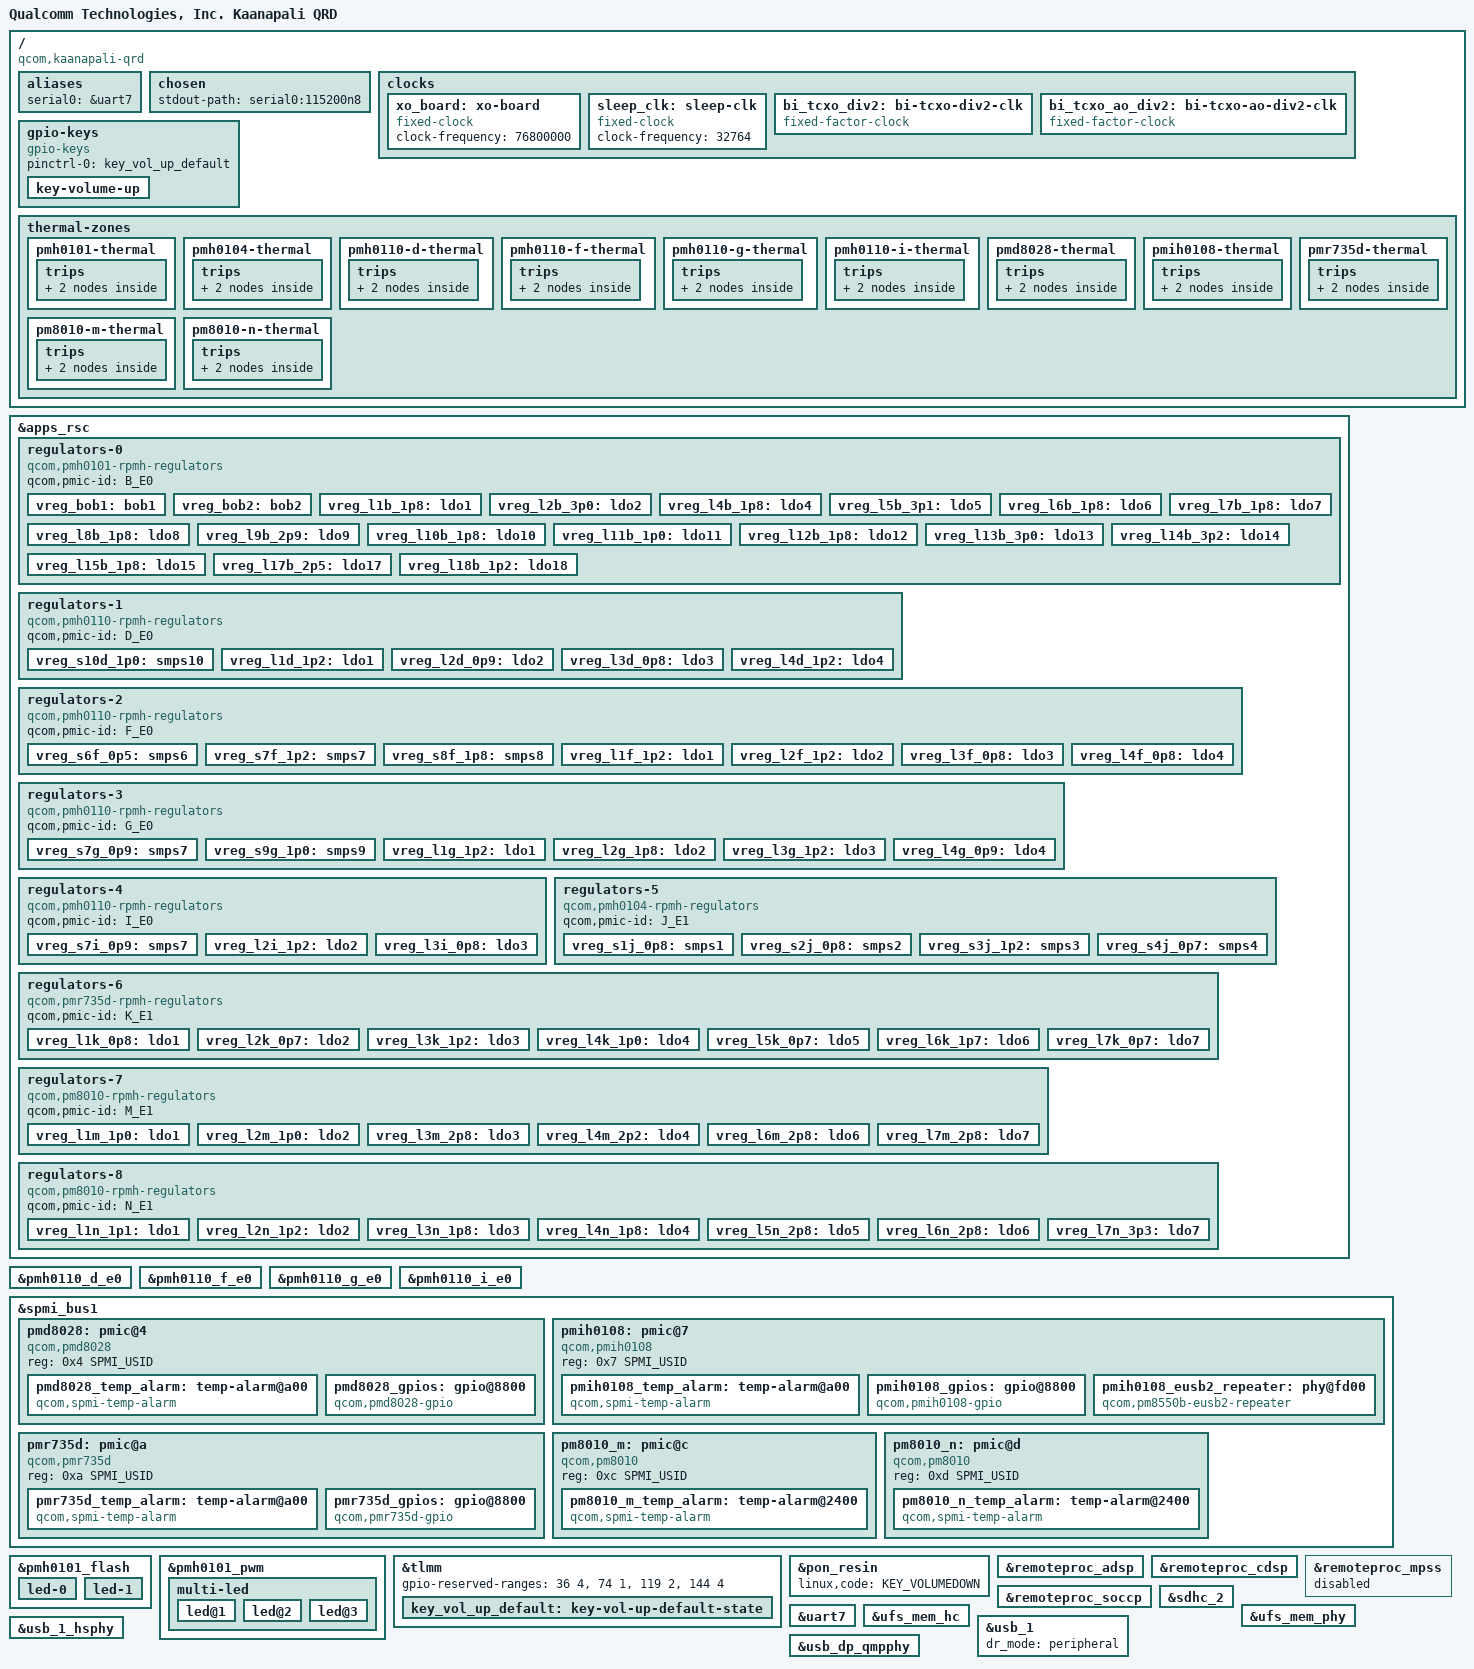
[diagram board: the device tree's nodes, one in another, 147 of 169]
// SPDX-License-Identifier: BSD-3-Clause
/*
 * Copyright (c) Qualcomm Technologies, Inc. and/or its subsidiaries.
 */

/dts-v1/;

#include <dt-bindings/gpio/gpio.h>
#include <dt-bindings/input/linux-event-codes.h>
#include <dt-bindings/leds/common.h>
#include <dt-bindings/regulator/qcom,rpmh-regulator.h>
#include "kaanapali.dtsi"

#define PMH0110_D_E0_SID 3
#define PMH0110_F_E0_SID 5
#define PMH0110_G_E0_SID 6
#define PMH0110_I_E0_SID 8
#define PMH0104_J_E1_SID 9

#include "pmk8850.dtsi"
#include "pmh0101.dtsi"
#include "pmh0110.dtsi"
#include "pmh0104.dtsi"

/ {
	model = "Qualcomm Technologies, Inc. Kaanapali QRD";
	compatible = "qcom,kaanapali-qrd", "qcom,kaanapali";
	chassis-type = "handset";

	aliases {
		serial0 = &uart7;
	};

	chosen {
		stdout-path = "serial0:115200n8";
	};

	clocks {
		xo_board: xo-board {
			compatible = "fixed-clock";
			clock-frequency = <76800000>;
			#clock-cells = <0>;
		};

		sleep_clk: sleep-clk {
			compatible = "fixed-clock";
			clock-frequency = <32764>;
			#clock-cells = <0>;
		};

		bi_tcxo_div2: bi-tcxo-div2-clk {
			compatible = "fixed-factor-clock";
			#clock-cells = <0>;

			clocks = <&rpmhcc RPMH_CXO_CLK>;
			clock-mult = <1>;
			clock-div = <2>;
		};

		bi_tcxo_ao_div2: bi-tcxo-ao-div2-clk {
			compatible = "fixed-factor-clock";
			#clock-cells = <0>;

			clocks = <&rpmhcc RPMH_CXO_CLK_A>;
			clock-mult = <1>;
			clock-div = <2>;
		};
	};

	gpio-keys {
		compatible = "gpio-keys";

		pinctrl-0 = <&key_vol_up_default>;
		pinctrl-names = "default";

		key-volume-up {
			label = "Volume Up";
			linux,code = <KEY_VOLUMEUP>;
			gpios = <&tlmm 101 GPIO_ACTIVE_LOW>;
			debounce-interval = <15>;
			linux,can-disable;
			wakeup-source;
		};
	};

	thermal-zones {
		pmh0101-thermal {
			polling-delay-passive = <100>;

			thermal-sensors = <&pmh0101_temp_alarm>;

			trips {
				trip0 {
					temperature = <95000>;
					hysteresis = <0>;
					type = "passive";
				};

				trip1 {
					temperature = <115000>;
					hysteresis = <0>;
					type = "hot";
				};
			};
		};

		pmh0104-thermal {
			polling-delay-passive = <100>;

			thermal-sensors = <&pmh0104_j_e1_temp_alarm>;

			trips {
				trip0 {
					temperature = <95000>;
					hysteresis = <0>;
					type = "passive";
				};

				trip1 {
					temperature = <115000>;
					hysteresis = <0>;
					type = "hot";
				};
			};
		};

		pmh0110-d-thermal {
			polling-delay-passive = <100>;

			thermal-sensors = <&pmh0110_d_e0_temp_alarm>;

			trips {
				trip0 {
					temperature = <95000>;
					hysteresis = <0>;
					type = "passive";
				};

				trip1 {
					temperature = <115000>;
					hysteresis = <0>;
					type = "hot";
				};
			};
		};

		pmh0110-f-thermal {
			polling-delay-passive = <100>;

			thermal-sensors = <&pmh0110_f_e0_temp_alarm>;

			trips {
				trip0 {
					temperature = <95000>;
					hysteresis = <0>;
					type = "passive";
				};

				trip1 {
					temperature = <115000>;
					hysteresis = <0>;
					type = "hot";
				};
			};
		};

		pmh0110-g-thermal {
			polling-delay-passive = <100>;

			thermal-sensors = <&pmh0110_g_e0_temp_alarm>;

			trips {
				trip0 {
					temperature = <95000>;
					hysteresis = <0>;
					type = "passive";
				};

				trip1 {
					temperature = <115000>;
					hysteresis = <0>;
					type = "hot";
				};
			};
		};

		pmh0110-i-thermal {
			polling-delay-passive = <100>;

			thermal-sensors = <&pmh0110_i_e0_temp_alarm>;

			trips {
				trip0 {
					temperature = <95000>;
					hysteresis = <0>;
					type = "passive";
				};

				trip1 {
					temperature = <115000>;
					hysteresis = <0>;
					type = "hot";
				};
			};
		};

		pmd8028-thermal {
			polling-delay-passive = <100>;
			thermal-sensors = <&pmd8028_temp_alarm>;

			trips {
				pmd8028_trip0: trip0 {
					temperature = <95000>;
					hysteresis = <0>;
					type = "passive";
				};

				pmd8028_trip1: trip1 {
					temperature = <115000>;
					hysteresis = <0>;
					type = "hot";
				};
			};
		};

		pmih0108-thermal {
			polling-delay-passive = <100>;
			thermal-sensors = <&pmih0108_temp_alarm>;

			trips {
				trip0 {
					temperature = <95000>;
					hysteresis = <0>;
					type = "passive";
				};

				trip1 {
					temperature = <115000>;
					hysteresis = <0>;
					type = "hot";
				};
			};
		};

		pmr735d-thermal {
			polling-delay-passive = <100>;

			thermal-sensors = <&pmr735d_temp_alarm>;

			trips {
				trip0 {
					temperature = <95000>;
					hysteresis = <0>;
					type = "passive";
				};

				trip1 {
					temperature = <115000>;
					hysteresis = <0>;
					type = "hot";
				};
			};
		};

		pm8010-m-thermal {
			polling-delay-passive = <100>;

			thermal-sensors = <&pm8010_m_temp_alarm>;

			trips {
				trip0 {
					temperature = <95000>;
					hysteresis = <0>;
					type = "passive";
				};

				trip1 {
					temperature = <115000>;
					hysteresis = <0>;
					type = "hot";
				};
			};
		};

		pm8010-n-thermal {
			polling-delay-passive = <100>;

			thermal-sensors = <&pm8010_n_temp_alarm>;

			trips {
				trip0 {
					temperature = <95000>;
					hysteresis = <0>;
					type = "passive";
				};

				trip1 {
					temperature = <115000>;
					hysteresis = <0>;
					type = "hot";
				};
			};
		};
	};
};

&apps_rsc {
	regulators-0 {
		compatible = "qcom,pmh0101-rpmh-regulators";

		qcom,pmic-id = "B_E0";

		vreg_bob1: bob1 {
			regulator-name = "vreg_bob1";
			regulator-min-microvolt = <3008000>;
			regulator-max-microvolt = <4000000>;
			regulator-initial-mode = <RPMH_REGULATOR_MODE_HPM>;
		};

		vreg_bob2: bob2 {
			regulator-name = "vreg_bob2";
			regulator-min-microvolt = <2704000>;
			regulator-max-microvolt = <3552000>;
			regulator-initial-mode = <RPMH_REGULATOR_MODE_HPM>;
		};

		vreg_l1b_1p8: ldo1 {
			regulator-name = "vreg_l1b_1p8";
			regulator-min-microvolt = <1800000>;
			regulator-max-microvolt = <1800000>;
			regulator-initial-mode = <RPMH_REGULATOR_MODE_AUTO>;
			regulator-allow-set-load;
			regulator-allowed-modes = <RPMH_REGULATOR_MODE_LPM
						   RPMH_REGULATOR_MODE_AUTO>;
		};

		vreg_l2b_3p0: ldo2 {
			regulator-name = "vreg_l2b_3p0";
			regulator-min-microvolt = <3008000>;
			regulator-max-microvolt = <3048000>;
			regulator-initial-mode = <RPMH_REGULATOR_MODE_AUTO>;
			regulator-allow-set-load;
			regulator-allowed-modes = <RPMH_REGULATOR_MODE_LPM
						   RPMH_REGULATOR_MODE_AUTO>;
		};

		vreg_l4b_1p8: ldo4 {
			regulator-name = "vreg_l4b_1p8";
			regulator-min-microvolt = <1800000>;
			regulator-max-microvolt = <1800000>;
			regulator-initial-mode = <RPMH_REGULATOR_MODE_AUTO>;
			regulator-allow-set-load;
			regulator-allowed-modes = <RPMH_REGULATOR_MODE_LPM
						   RPMH_REGULATOR_MODE_AUTO>;
		};

		vreg_l5b_3p1: ldo5 {
			regulator-name = "vreg_l5b_3p1";
			regulator-min-microvolt = <3100000>;
			regulator-max-microvolt = <3148000>;
			regulator-initial-mode = <RPMH_REGULATOR_MODE_AUTO>;
			regulator-allow-set-load;
			regulator-allowed-modes = <RPMH_REGULATOR_MODE_LPM
						   RPMH_REGULATOR_MODE_AUTO>;
		};

		vreg_l6b_1p8: ldo6 {
			regulator-name = "vreg_l6b_1p8";
			regulator-min-microvolt = <1800000>;
			regulator-max-microvolt = <3008000>;
			regulator-initial-mode = <RPMH_REGULATOR_MODE_AUTO>;
			regulator-allow-set-load;
			regulator-allowed-modes = <RPMH_REGULATOR_MODE_LPM
						   RPMH_REGULATOR_MODE_AUTO>;
		};

		vreg_l7b_1p8: ldo7 {
			regulator-name = "vreg_l7b_1p8";
			regulator-min-microvolt = <1800000>;
			regulator-max-microvolt = <3008000>;
			regulator-initial-mode = <RPMH_REGULATOR_MODE_AUTO>;
			regulator-allow-set-load;
			regulator-allowed-modes = <RPMH_REGULATOR_MODE_LPM
						   RPMH_REGULATOR_MODE_AUTO>;
		};

		vreg_l8b_1p8: ldo8 {
			regulator-name = "vreg_l8b_1p8";
			regulator-min-microvolt = <1800000>;
			regulator-max-microvolt = <3008000>;
			regulator-initial-mode = <RPMH_REGULATOR_MODE_AUTO>;
			regulator-allow-set-load;
			regulator-allowed-modes = <RPMH_REGULATOR_MODE_LPM
						   RPMH_REGULATOR_MODE_AUTO>;
		};

		vreg_l9b_2p9: ldo9 {
			regulator-name = "vreg_l9b_2p9";
			regulator-min-microvolt = <2960000>;
			regulator-max-microvolt = <3008000>;
			regulator-initial-mode = <RPMH_REGULATOR_MODE_HPM>;
			regulator-allow-set-load;
			regulator-allowed-modes = <RPMH_REGULATOR_MODE_LPM
						   RPMH_REGULATOR_MODE_HPM>;
		};

		vreg_l10b_1p8: ldo10 {
			regulator-name = "vreg_l10b_1p8";
			regulator-min-microvolt = <1800000>;
			regulator-max-microvolt = <1800000>;
			regulator-initial-mode = <RPMH_REGULATOR_MODE_AUTO>;
			regulator-allow-set-load;
			regulator-allowed-modes = <RPMH_REGULATOR_MODE_LPM
						   RPMH_REGULATOR_MODE_AUTO>;
		};

		vreg_l11b_1p0: ldo11 {
			regulator-name = "vreg_l11b_1p0";
			regulator-min-microvolt = <1000000>;
			regulator-max-microvolt = <1292000>;
			regulator-initial-mode = <RPMH_REGULATOR_MODE_AUTO>;
			regulator-allow-set-load;
			regulator-allowed-modes = <RPMH_REGULATOR_MODE_LPM
						   RPMH_REGULATOR_MODE_AUTO>;
		};

		vreg_l12b_1p8: ldo12 {
			regulator-name = "vreg_l12b_1p8";
			regulator-min-microvolt = <1200000>;
			regulator-max-microvolt = <1800000>;
			regulator-initial-mode = <RPMH_REGULATOR_MODE_AUTO>;
			regulator-allow-set-load;
			regulator-allowed-modes = <RPMH_REGULATOR_MODE_LPM
						   RPMH_REGULATOR_MODE_AUTO>;
		};

		vreg_l13b_3p0: ldo13 {
			regulator-name = "vreg_l13b_3p0";
			regulator-min-microvolt = <3000000>;
			regulator-max-microvolt = <3000000>;
			regulator-initial-mode = <RPMH_REGULATOR_MODE_AUTO>;
			regulator-allow-set-load;
			regulator-allowed-modes = <RPMH_REGULATOR_MODE_LPM
						   RPMH_REGULATOR_MODE_AUTO>;
		};

		vreg_l14b_3p2: ldo14 {
			regulator-name = "vreg_l14b_3p2";
			regulator-min-microvolt = <3200000>;
			regulator-max-microvolt = <3200000>;
			regulator-initial-mode = <RPMH_REGULATOR_MODE_AUTO>;
			regulator-allow-set-load;
			regulator-allowed-modes = <RPMH_REGULATOR_MODE_LPM
						   RPMH_REGULATOR_MODE_AUTO>;
		};

		vreg_l15b_1p8: ldo15 {
			regulator-name = "vreg_l15b_1p8";
			regulator-min-microvolt = <1800000>;
			regulator-max-microvolt = <1800000>;
			regulator-initial-mode = <RPMH_REGULATOR_MODE_AUTO>;
			regulator-allow-set-load;
			regulator-allowed-modes = <RPMH_REGULATOR_MODE_LPM
						   RPMH_REGULATOR_MODE_AUTO>;
		};

		vreg_l17b_2p5: ldo17 {
			regulator-name = "vreg_l17b_2p5";
			regulator-min-microvolt = <2504000>;
			regulator-max-microvolt = <2504000>;
			regulator-initial-mode = <RPMH_REGULATOR_MODE_HPM>;
			regulator-allow-set-load;
			regulator-allowed-modes = <RPMH_REGULATOR_MODE_LPM
						   RPMH_REGULATOR_MODE_HPM>;
		};

		vreg_l18b_1p2: ldo18 {
			regulator-name = "vreg_l18b_1p2";
			regulator-min-microvolt = <1200000>;
			regulator-max-microvolt = <1200000>;
			regulator-initial-mode = <RPMH_REGULATOR_MODE_AUTO>;
			regulator-allow-set-load;
			regulator-allowed-modes = <RPMH_REGULATOR_MODE_LPM
						   RPMH_REGULATOR_MODE_AUTO>;
		};
	};

	regulators-1 {
		compatible = "qcom,pmh0110-rpmh-regulators";

		qcom,pmic-id = "D_E0";

		vreg_s10d_1p0: smps10 {
			regulator-name = "vreg_s10d_1p0";
			regulator-min-microvolt = <1000000>;
			regulator-max-microvolt = <1100000>;
			regulator-initial-mode = <RPMH_REGULATOR_MODE_HPM>;
		};

		vreg_l1d_1p2: ldo1 {
			regulator-name = "vreg_l1d_1p2";
			regulator-min-microvolt = <1200000>;
			regulator-max-microvolt = <1256000>;
			regulator-initial-mode = <RPMH_REGULATOR_MODE_AUTO>;
			regulator-allow-set-load;
			regulator-allowed-modes = <RPMH_REGULATOR_MODE_LPM
						   RPMH_REGULATOR_MODE_AUTO>;
		};

		vreg_l2d_0p9: ldo2 {
			regulator-name = "vreg_l2d_0p9";
			regulator-min-microvolt = <912000>;
			regulator-max-microvolt = <958000>;
			regulator-initial-mode = <RPMH_REGULATOR_MODE_AUTO>;
			regulator-allow-set-load;
			regulator-allowed-modes = <RPMH_REGULATOR_MODE_LPM
						   RPMH_REGULATOR_MODE_AUTO>;
		};

		vreg_l3d_0p8: ldo3 {
			regulator-name = "vreg_l3d_0p8";
			regulator-min-microvolt = <880000>;
			regulator-max-microvolt = <880000>;
			regulator-initial-mode = <RPMH_REGULATOR_MODE_AUTO>;
			regulator-allow-set-load;
			regulator-allowed-modes = <RPMH_REGULATOR_MODE_LPM
						   RPMH_REGULATOR_MODE_AUTO>;
		};

		vreg_l4d_1p2: ldo4 {
			regulator-name = "vreg_l4d_1p2";
			regulator-min-microvolt = <1200000>;
			regulator-max-microvolt = <1200000>;
			regulator-initial-mode = <RPMH_REGULATOR_MODE_AUTO>;
			regulator-allow-set-load;
			regulator-allowed-modes = <RPMH_REGULATOR_MODE_LPM
						   RPMH_REGULATOR_MODE_AUTO>;
		};
	};

	regulators-2 {
		compatible = "qcom,pmh0110-rpmh-regulators";

		qcom,pmic-id = "F_E0";

		vreg_s6f_0p5: smps6 {
			regulator-name = "vreg_s6f_0p5";
			regulator-min-microvolt = <300000>;
			regulator-max-microvolt = <570000>;
			regulator-initial-mode = <RPMH_REGULATOR_MODE_HPM>;
		};

		vreg_s7f_1p2: smps7 {
			regulator-name = "vreg_s7f_1p2";
			regulator-min-microvolt = <1224000>;
			regulator-max-microvolt = <1372000>;
			regulator-initial-mode = <RPMH_REGULATOR_MODE_HPM>;
		};

		vreg_s8f_1p8: smps8 {
			regulator-name = "vreg_s8f_1p8";
			regulator-min-microvolt = <1800000>;
			regulator-max-microvolt = <2000000>;
			regulator-initial-mode = <RPMH_REGULATOR_MODE_HPM>;
		};

		vreg_l1f_1p2: ldo1 {
			regulator-name = "vreg_l1f_1p2";
			regulator-min-microvolt = <1200000>;
			regulator-max-microvolt = <1200000>;
			regulator-initial-mode = <RPMH_REGULATOR_MODE_AUTO>;
			regulator-allow-set-load;
			regulator-allowed-modes = <RPMH_REGULATOR_MODE_LPM
						   RPMH_REGULATOR_MODE_AUTO>;
		};

		vreg_l2f_1p2: ldo2 {
			regulator-name = "vreg_l2f_1p2";
			regulator-min-microvolt = <1200000>;
			regulator-max-microvolt = <1200000>;
			regulator-initial-mode = <RPMH_REGULATOR_MODE_AUTO>;
			regulator-allow-set-load;
			regulator-allowed-modes = <RPMH_REGULATOR_MODE_LPM
						   RPMH_REGULATOR_MODE_AUTO>;
		};

		vreg_l3f_0p8: ldo3 {
			regulator-name = "vreg_l3f_0p8";
			regulator-min-microvolt = <880000>;
			regulator-max-microvolt = <936000>;
			regulator-initial-mode = <RPMH_REGULATOR_MODE_AUTO>;
			regulator-allow-set-load;
			regulator-allowed-modes = <RPMH_REGULATOR_MODE_LPM
						   RPMH_REGULATOR_MODE_AUTO>;
		};

		vreg_l4f_0p8: ldo4 {
			regulator-name = "vreg_l4f_0p8";
			regulator-min-microvolt = <880000>;
			regulator-max-microvolt = <912000>;
			regulator-initial-mode = <RPMH_REGULATOR_MODE_AUTO>;
			regulator-allow-set-load;
			regulator-allowed-modes = <RPMH_REGULATOR_MODE_LPM
						   RPMH_REGULATOR_MODE_AUTO>;
		};
	};

	regulators-3 {
		compatible = "qcom,pmh0110-rpmh-regulators";

		qcom,pmic-id = "G_E0";

		vreg_s7g_0p9: smps7 {
			regulator-name = "vreg_s7g_0p9";
			regulator-min-microvolt = <880000>;
			regulator-max-microvolt = <1100000>;
			regulator-initial-mode = <RPMH_REGULATOR_MODE_HPM>;
		};

		vreg_s9g_1p0: smps9 {
			regulator-name = "vreg_s9g_1p0";
			regulator-min-microvolt = <1000000>;
			regulator-max-microvolt = <1100000>;
			regulator-initial-mode = <RPMH_REGULATOR_MODE_HPM>;
		};

		vreg_l1g_1p2: ldo1 {
			regulator-name = "vreg_l1g_1p2";
			regulator-min-microvolt = <1200000>;
			regulator-max-microvolt = <1200000>;
			regulator-initial-mode = <RPMH_REGULATOR_MODE_AUTO>;
			regulator-allow-set-load;
			regulator-allowed-modes = <RPMH_REGULATOR_MODE_LPM
						   RPMH_REGULATOR_MODE_AUTO>;
		};

		vreg_l2g_1p8: ldo2 {
			regulator-name = "vreg_l2g_1p8";
			regulator-min-microvolt = <1800000>;
			regulator-max-microvolt = <1800000>;
			regulator-initial-mode = <RPMH_REGULATOR_MODE_AUTO>;
			regulator-allow-set-load;
			regulator-allowed-modes = <RPMH_REGULATOR_MODE_LPM
						   RPMH_REGULATOR_MODE_AUTO>;
		};

		vreg_l3g_1p2: ldo3 {
			regulator-name = "vreg_l3g_1p2";
			regulator-min-microvolt = <1200000>;
			regulator-max-microvolt = <1200000>;
			regulator-initial-mode = <RPMH_REGULATOR_MODE_AUTO>;
			regulator-allow-set-load;
			regulator-allowed-modes = <RPMH_REGULATOR_MODE_LPM
						   RPMH_REGULATOR_MODE_AUTO>;
		};

		vreg_l4g_0p9: ldo4 {
			regulator-name = "vreg_l4g_0p9";
			regulator-min-microvolt = <880000>;
			regulator-max-microvolt = <920000>;
			regulator-initial-mode = <RPMH_REGULATOR_MODE_AUTO>;
			regulator-allow-set-load;
			regulator-allowed-modes = <RPMH_REGULATOR_MODE_LPM
						   RPMH_REGULATOR_MODE_AUTO>;
		};
	};

	regulators-4 {
		compatible = "qcom,pmh0110-rpmh-regulators";

		qcom,pmic-id = "I_E0";

		vreg_s7i_0p9: smps7 {
			regulator-name = "vreg_s7i_0p9";
			regulator-min-microvolt = <900000>;
			regulator-max-microvolt = <972000>;
			regulator-initial-mode = <RPMH_REGULATOR_MODE_HPM>;
		};

		vreg_l2i_1p2: ldo2 {
			regulator-name = "vreg_l2i_1p2";
			regulator-min-microvolt = <1200000>;
			regulator-max-microvolt = <1200000>;
			regulator-initial-mode = <RPMH_REGULATOR_MODE_AUTO>;
			regulator-allow-set-load;
			regulator-allowed-modes = <RPMH_REGULATOR_MODE_LPM
						   RPMH_REGULATOR_MODE_AUTO>;
		};

		vreg_l3i_0p8: ldo3 {
			regulator-name = "vreg_l3i_0p8";
			regulator-min-microvolt = <880000>;
			regulator-max-microvolt = <920000>;
			regulator-initial-mode = <RPMH_REGULATOR_MODE_AUTO>;
			regulator-allow-set-load;
			regulator-allowed-modes = <RPMH_REGULATOR_MODE_LPM
						   RPMH_REGULATOR_MODE_AUTO>;
		};
	};

	regulators-5 {
		compatible = "qcom,pmh0104-rpmh-regulators";

		qcom,pmic-id = "J_E1";

		vreg_s1j_0p8: smps1 {
			regulator-name = "vreg_s1j_0p8";
			regulator-min-microvolt = <400000>;
			regulator-max-microvolt = <1000000>;
			regulator-initial-mode = <RPMH_REGULATOR_MODE_HPM>;
		};

		vreg_s2j_0p8: smps2 {
			regulator-name = "vreg_s2j_0p8";
			regulator-min-microvolt = <500000>;
			regulator-max-microvolt = <1100000>;
			regulator-initial-mode = <RPMH_REGULATOR_MODE_HPM>;
		};

		vreg_s3j_1p2: smps3 {
			regulator-name = "vreg_s3j_1p2";
			regulator-min-microvolt = <1200000>;
			regulator-max-microvolt = <1300000>;
			regulator-initial-mode = <RPMH_REGULATOR_MODE_HPM>;
		};

		vreg_s4j_0p7: smps4 {
			regulator-name = "vreg_s4j_0p7";
			regulator-min-microvolt = <300000>;
			regulator-max-microvolt = <1000000>;
			regulator-initial-mode = <RPMH_REGULATOR_MODE_HPM>;
		};
	};

	regulators-6 {
		compatible = "qcom,pmr735d-rpmh-regulators";

		qcom,pmic-id = "K_E1";

		vreg_l1k_0p8: ldo1 {
			regulator-name = "vreg_l1k_0p8";
			regulator-min-microvolt = <300000>;
			regulator-max-microvolt = <1100000>;
			regulator-initial-mode = <RPMH_REGULATOR_MODE_HPM>;
			regulator-allow-set-load;
			regulator-allowed-modes = <RPMH_REGULATOR_MODE_LPM
						   RPMH_REGULATOR_MODE_HPM>;
		};

		vreg_l2k_0p7: ldo2 {
			regulator-name = "vreg_l2k_0p7";
			regulator-min-microvolt = <700000>;
			regulator-max-microvolt = <1000000>;
			regulator-initial-mode = <RPMH_REGULATOR_MODE_HPM>;
			regulator-allow-set-load;
			regulator-allowed-modes = <RPMH_REGULATOR_MODE_LPM
						   RPMH_REGULATOR_MODE_HPM>;
		};

		vreg_l3k_1p2: ldo3 {
			regulator-name = "vreg_l3k_1p2";
			regulator-min-microvolt = <1200000>;
			regulator-max-microvolt = <1200000>;
			regulator-initial-mode = <RPMH_REGULATOR_MODE_HPM>;
			regulator-allow-set-load;
			regulator-allowed-modes = <RPMH_REGULATOR_MODE_LPM
						   RPMH_REGULATOR_MODE_HPM>;
		};

		vreg_l4k_1p0: ldo4 {
			regulator-name = "vreg_l4k_1p0";
			regulator-min-microvolt = <1000000>;
			regulator-max-microvolt = <1200000>;
			regulator-initial-mode = <RPMH_REGULATOR_MODE_HPM>;
			regulator-allow-set-load;
			regulator-allowed-modes = <RPMH_REGULATOR_MODE_LPM
						   RPMH_REGULATOR_MODE_HPM>;
		};

		vreg_l5k_0p7: ldo5 {
			regulator-name = "vreg_l5k_0p7";
			regulator-min-microvolt = <700000>;
			regulator-max-microvolt = <1000000>;
			regulator-initial-mode = <RPMH_REGULATOR_MODE_HPM>;
			regulator-allow-set-load;
			regulator-allowed-modes = <RPMH_REGULATOR_MODE_LPM
						   RPMH_REGULATOR_MODE_HPM>;
		};

		vreg_l6k_1p7: ldo6 {
			regulator-name = "vreg_l6k_1p7";
			regulator-min-microvolt = <1700000>;
			regulator-max-microvolt = <2000000>;
			regulator-initial-mode = <RPMH_REGULATOR_MODE_HPM>;
			regulator-allow-set-load;
			regulator-allowed-modes = <RPMH_REGULATOR_MODE_LPM
						   RPMH_REGULATOR_MODE_HPM>;
		};

		vreg_l7k_0p7: ldo7 {
			regulator-name = "vreg_l7k_0p7";
			regulator-min-microvolt = <700000>;
			regulator-max-microvolt = <848000>;
			regulator-initial-mode = <RPMH_REGULATOR_MODE_HPM>;
			regulator-allow-set-load;
			regulator-allowed-modes = <RPMH_REGULATOR_MODE_LPM
						   RPMH_REGULATOR_MODE_HPM>;
		};
	};

	regulators-7 {
		compatible = "qcom,pm8010-rpmh-regulators";

		qcom,pmic-id = "M_E1";

		vreg_l1m_1p0: ldo1 {
			regulator-name = "vreg_l1m_1p0";
			regulator-min-microvolt = <1000000>;
			regulator-max-microvolt = <1100000>;
			regulator-initial-mode = <RPMH_REGULATOR_MODE_HPM>;
			regulator-allow-set-load;
			regulator-allowed-modes = <RPMH_REGULATOR_MODE_LPM
						   RPMH_REGULATOR_MODE_HPM>;
		};

		vreg_l2m_1p0: ldo2 {
			regulator-name = "vreg_l2m_1p0";
			regulator-min-microvolt = <1096000>;
			regulator-max-microvolt = <1104000>;
			regulator-initial-mode = <RPMH_REGULATOR_MODE_HPM>;
			regulator-allow-set-load;
			regulator-allowed-modes = <RPMH_REGULATOR_MODE_LPM
						   RPMH_REGULATOR_MODE_HPM>;
		};

		vreg_l3m_2p8: ldo3 {
			regulator-name = "vreg_l3m_2p8";
			regulator-min-microvolt = <2800000>;
			regulator-max-microvolt = <2900000>;
			regulator-initial-mode = <RPMH_REGULATOR_MODE_HPM>;
		};

		vreg_l4m_2p2: ldo4 {
			regulator-name = "vreg_l4m_2p2";
			regulator-min-microvolt = <2200000>;
			regulator-max-microvolt = <2200000>;
			regulator-initial-mode = <RPMH_REGULATOR_MODE_HPM>;
		};

		vreg_l6m_2p8: ldo6 {
			regulator-name = "vreg_l6m_2p8";
			regulator-min-microvolt = <2800000>;
			regulator-max-microvolt = <2800000>;
			regulator-initial-mode = <RPMH_REGULATOR_MODE_HPM>;
		};

		vreg_l7m_2p8: ldo7 {
			regulator-name = "vreg_l7m_2p8";
			regulator-min-microvolt = <2800000>;
			regulator-max-microvolt = <2800000>;
			regulator-initial-mode = <RPMH_REGULATOR_MODE_HPM>;
		};
	};

	regulators-8 {
		compatible = "qcom,pm8010-rpmh-regulators";

		qcom,pmic-id = "N_E1";

		vreg_l1n_1p1: ldo1 {
			regulator-name = "vreg_l1n_1p1";
			regulator-min-microvolt = <1096000>;
			regulator-max-microvolt = <1104000>;
			regulator-initial-mode = <RPMH_REGULATOR_MODE_HPM>;
			regulator-allow-set-load;
			regulator-allowed-modes = <RPMH_REGULATOR_MODE_LPM
						   RPMH_REGULATOR_MODE_HPM>;
		};

		vreg_l2n_1p2: ldo2 {
			regulator-name = "vreg_l2n_1p2";
			regulator-min-microvolt = <1200000>;
			regulator-max-microvolt = <1200000>;
			regulator-initial-mode = <RPMH_REGULATOR_MODE_HPM>;
			regulator-allow-set-load;
			regulator-allowed-modes = <RPMH_REGULATOR_MODE_LPM
						   RPMH_REGULATOR_MODE_HPM>;
		};

		vreg_l3n_1p8: ldo3 {
			regulator-name = "vreg_l3n_1p8";
			regulator-min-microvolt = <1800000>;
			regulator-max-microvolt = <1800000>;
			regulator-initial-mode = <RPMH_REGULATOR_MODE_HPM>;
		};

		vreg_l4n_1p8: ldo4 {
			regulator-name = "vreg_l4n_1p8";
			regulator-min-microvolt = <1800000>;
			regulator-max-microvolt = <1800000>;
			regulator-initial-mode = <RPMH_REGULATOR_MODE_HPM>;
		};

		vreg_l5n_2p8: ldo5 {
			regulator-name = "vreg_l5n_2p8";
			regulator-min-microvolt = <2800000>;
			regulator-max-microvolt = <2800000>;
			regulator-initial-mode = <RPMH_REGULATOR_MODE_HPM>;
		};

		vreg_l6n_2p8: ldo6 {
			regulator-name = "vreg_l6n_2p8";
			regulator-min-microvolt = <2800000>;
			regulator-max-microvolt = <2800000>;
			regulator-initial-mode = <RPMH_REGULATOR_MODE_HPM>;
		};

		vreg_l7n_3p3: ldo7 {
			regulator-name = "vreg_l7n_3p3";
			regulator-min-microvolt = <3304000>;
			regulator-max-microvolt = <3304000>;
			regulator-initial-mode = <RPMH_REGULATOR_MODE_HPM>;
		};
	};
};

&pmh0110_d_e0 {
	status = "okay";
};

&pmh0110_f_e0 {
	status = "okay";
};

&pmh0110_g_e0 {
	status = "okay";
};

&pmh0110_i_e0 {
	status = "okay";
};

&spmi_bus1 {
	pmd8028: pmic@4 {
		compatible = "qcom,pmd8028", "qcom,spmi-pmic";
		reg = <0x4 SPMI_USID>;
		#address-cells = <1>;
		#size-cells = <0>;

		pmd8028_temp_alarm: temp-alarm@a00 {
			compatible = "qcom,spmi-temp-alarm";
			reg = <0xa00>;
			interrupts = <0x4 0xa 0x0 IRQ_TYPE_EDGE_BOTH>;
			#thermal-sensor-cells = <0>;
		};

		pmd8028_gpios: gpio@8800 {
			compatible = "qcom,pmd8028-gpio", "qcom,spmi-gpio";
			reg = <0x8800>;
			gpio-controller;
			gpio-ranges = <&pmd8028_gpios 0 0 4>;
			#gpio-cells = <2>;
			interrupt-controller;
			#interrupt-cells = <2>;
		};
	};

	pmih0108: pmic@7 {
		compatible = "qcom,pmih0108", "qcom,spmi-pmic";
		reg = <0x7 SPMI_USID>;
		#address-cells = <1>;
		#size-cells = <0>;

		pmih0108_temp_alarm: temp-alarm@a00 {
			compatible = "qcom,spmi-temp-alarm";
			reg = <0xa00>;
			interrupts = <0x7 0xa 0x0 IRQ_TYPE_EDGE_BOTH>;
			#thermal-sensor-cells = <0>;
		};

		pmih0108_gpios: gpio@8800 {
			compatible = "qcom,pmih0108-gpio", "qcom,spmi-gpio";
			reg = <0x8800>;
			gpio-controller;
			gpio-ranges = <&pmih0108_gpios 0 0 18>;
			#gpio-cells = <2>;
			interrupt-controller;
			#interrupt-cells = <2>;
		};

		pmih0108_eusb2_repeater: phy@fd00 {
			compatible = "qcom,pm8550b-eusb2-repeater";
			reg = <0xfd00>;
			#phy-cells = <0>;
			vdd18-supply = <&vreg_l15b_1p8>;
			vdd3-supply = <&vreg_l5b_3p1>;
		};
	};

	pmr735d: pmic@a {
		compatible = "qcom,pmr735d", "qcom,spmi-pmic";
		reg = <0xa SPMI_USID>;
		#address-cells = <1>;
		#size-cells = <0>;

		pmr735d_temp_alarm: temp-alarm@a00 {
			compatible = "qcom,spmi-temp-alarm";
			reg = <0xa00>;
			interrupts = <0xa 0xa 0x0 IRQ_TYPE_EDGE_BOTH>;
			#thermal-sensor-cells = <0>;
		};

		pmr735d_gpios: gpio@8800 {
			compatible = "qcom,pmr735d-gpio", "qcom,spmi-gpio";
			reg = <0x8800>;
			gpio-controller;
			gpio-ranges = <&pmr735d_gpios 0 0 2>;
			#gpio-cells = <2>;
			interrupt-controller;
			#interrupt-cells = <2>;
		};
	};

	pm8010_m: pmic@c {
		compatible = "qcom,pm8010", "qcom,spmi-pmic";
		reg = <0xc SPMI_USID>;
		#address-cells = <1>;
		#size-cells = <0>;

		pm8010_m_temp_alarm: temp-alarm@2400 {
			compatible = "qcom,spmi-temp-alarm";
			reg = <0x2400>;
			interrupts = <0xc 0x24 0x0 IRQ_TYPE_EDGE_BOTH>;
			#thermal-sensor-cells = <0>;
		};
	};

	pm8010_n: pmic@d {
		compatible = "qcom,pm8010", "qcom,spmi-pmic";
		reg = <0xd SPMI_USID>;
		#address-cells = <1>;
		#size-cells = <0>;

		pm8010_n_temp_alarm: temp-alarm@2400 {
			compatible = "qcom,spmi-temp-alarm";
			reg = <0x2400>;
			interrupts = <0xd 0x24 0x0 IRQ_TYPE_EDGE_BOTH>;
			#thermal-sensor-cells = <0>;
		};
	};
};

&pmh0101_flash {
	status = "okay";

	led-0 {
		function = LED_FUNCTION_FLASH;
		function-enumerator = <0>;
		color = <LED_COLOR_ID_YELLOW>;
		led-sources = <1>, <4>;
		led-max-microamp = <500000>;
		flash-max-microamp = <2000000>;
		flash-max-timeout-us = <1280000>;
	};

	led-1 {
		function = LED_FUNCTION_FLASH;
		function-enumerator = <1>;
		color = <LED_COLOR_ID_WHITE>;
		led-sources = <2>, <3>;
		led-max-microamp = <500000>;
		flash-max-microamp = <2000000>;
		flash-max-timeout-us = <1280000>;
	};
};

&pmh0101_pwm {
	status = "okay";

	multi-led {
		color = <LED_COLOR_ID_RGB>;
		function = LED_FUNCTION_STATUS;

		#address-cells = <1>;
		#size-cells = <0>;

		led@1 {
			reg = <1>;
			color = <LED_COLOR_ID_RED>;
		};

		led@2 {
			reg = <2>;
			color = <LED_COLOR_ID_GREEN>;
		};

		led@3 {
			reg = <3>;
			color = <LED_COLOR_ID_BLUE>;
		};
	};
};

&tlmm {
	key_vol_up_default: key-vol-up-default-state {
		pins = "gpio101";
		function = "gpio";
		output-disable;
		bias-pull-up;
	};
};

&pon_resin {
	linux,code = <KEY_VOLUMEDOWN>;

	status = "okay";
};

&remoteproc_adsp {
	firmware-name = "qcom/kaanapali/adsp.mbn",
			"qcom/kaanapali/adsp_dtb.mbn";

	status = "okay";
};

&remoteproc_cdsp {
	firmware-name = "qcom/kaanapali/cdsp.mbn",
			"qcom/kaanapali/cdsp_dtb.mbn";

	status = "okay";
};

&remoteproc_mpss {
	firmware-name = "qcom/kaanapali/modem.mbn",
			"qcom/kaanapali/modem_dtb.mbn";

	/* Modem crashes after some time for OEMPD load failure */
	status = "fail";
};

&remoteproc_soccp {
	firmware-name = "qcom/kaanapali/soccp.mbn",
			"qcom/kaanapali/soccp_dtb.mbn";
};

&sdhc_2 {
	cd-gpios = <&tlmm 55 GPIO_ACTIVE_LOW>;

	vmmc-supply = <&vreg_l9b_2p9>;
	vqmmc-supply = <&vreg_l8b_1p8>;

	bus-width = <4>;
	no-sdio;
	no-mmc;

	pinctrl-0 = <&sdc2_default>;
	pinctrl-1 = <&sdc2_sleep>;
	pinctrl-names = "default", "sleep";

	status = "okay";
};

&tlmm {
	gpio-reserved-ranges = <36 4>, /* NFC eSE SPI */
			       <74 1>, /* eSE */
			       <119 2>, /* SoCCP */
			       <144 4>; /* CXM UART */
};

&uart7 {
	status = "okay";
};

&ufs_mem_hc {
	reset-gpios = <&tlmm 217 GPIO_ACTIVE_LOW>;

	vcc-supply = <&vreg_l17b_2p5>;
	vcc-max-microamp = <1200000>;
	vccq-supply = <&vreg_l4d_1p2>;
	vccq-max-microamp = <1200000>;

	status = "okay";
};

&ufs_mem_phy {
	vdda-phy-supply = <&vreg_l4g_0p9>;
	vdda-pll-supply = <&vreg_l1d_1p2>;

	status = "okay";
};

&usb_1 {
	dr_mode = "peripheral";

	status = "okay";
};

&usb_1_hsphy {
	vdd-supply = <&vreg_l4f_0p8>;
	vdda12-supply = <&vreg_l1d_1p2>;

	phys = <&pmih0108_eusb2_repeater>;

	status = "okay";
};

&usb_dp_qmpphy {
	vdda-phy-supply = <&vreg_l1d_1p2>;
	vdda-pll-supply = <&vreg_l4f_0p8>;

	status = "okay";
};
